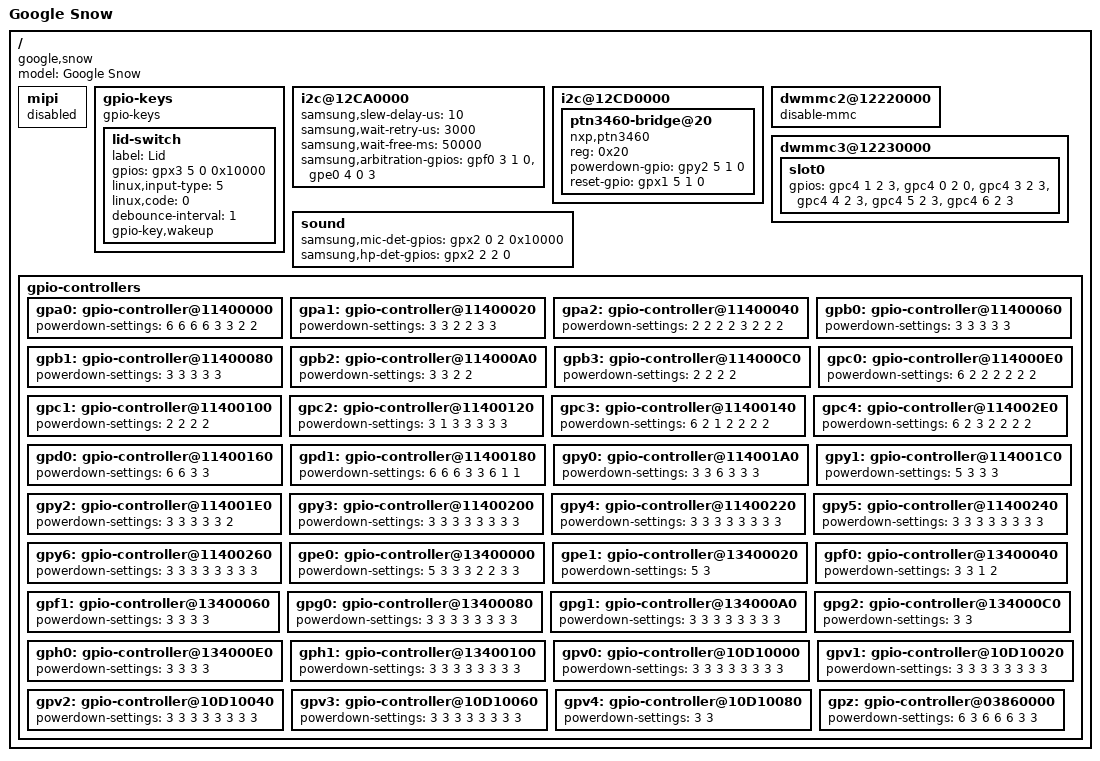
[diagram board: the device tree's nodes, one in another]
/*
 * Google Snow board device tree source
 *
 * Copyright (c) 2012 Google, Inc
 *
 * This program is free software; you can redistribute it and/or modify
 * it under the terms of the GNU General Public License version 2 as
 * published by the Free Software Foundation.
*/

/dts-v1/;
/include/ "exynos5250.dtsi"
/include/ "cros5250-common.dtsi"

/ {
	model = "Google Snow";
	compatible = "google,snow", "samsung,exynos5250";

	mipi {
		status = "disabled";
	};

	gpio-keys {
		compatible = "gpio-keys";

		lid-switch {
			label = "Lid";
			gpios = <&gpx3 5 0 0x10000 0>;
			linux,input-type = <5>; /* EV_SW */
			linux,code = <0>; /* SW_LID */
			debounce-interval = <1>;
			gpio-key,wakeup;
		};
	};
	i2c@12CA0000 {
		samsung,slew-delay-us = <10>;
		samsung,wait-retry-us = <3000>;
		samsung,wait-free-ms = <50000>;
		samsung,arbitration-gpios = <&gpf0 3 1 0 0>,
			<&gpe0 4 0 3 0>;
	};
	i2c@12CD0000 {
		ptn3460-bridge@20 {
			compatible = "nxp,ptn3460";
			reg = <0x20>;
			powerdown-gpio = <&gpy2 5 1 0 0>;
			reset-gpio = <&gpx1 5 1 0 0>;
		};
	};

	dwmmc2@12220000 {
		disable-mmc;
	};

	/*
	 * On Snow we've got SIP WiFi and so can keep drive strengths low to
	 * reduce EMI.
	 */
	dwmmc3@12230000 {
		slot0 {
			gpios = <&gpc4 1 2 3 0>, <&gpc4 0 2 0 0>,
				<&gpc4 3 2 3 0>, <&gpc4 4 2 3 0>,
				<&gpc4 5 2 3 0>, <&gpc4 6 2 3 0>;
		};
	};

	sound {
		samsung,mic-det-gpios = <&gpx2 0 2 0x10000 0>;
		samsung,hp-det-gpios = <&gpx2 2 2 0 0>;
	};

	gpio-controllers {
		gpa0: gpio-controller@11400000 {
			powerdown-settings = <6 6 6 6 3 3 2 2>;
		};

		gpa1: gpio-controller@11400020 {
			powerdown-settings = <3 3 2 2 3 3>;
		};

		gpa2: gpio-controller@11400040 {
			powerdown-settings = <2 2 2 2 3 2 2 2>;
		};

		gpb0: gpio-controller@11400060 {
			powerdown-settings = <3 3 3 3 3>;
		};

		gpb1: gpio-controller@11400080 {
			powerdown-settings = <3 3 3 3 3>;
		};

		gpb2: gpio-controller@114000A0 {
			powerdown-settings = <3 3 2 2>;
		};

		gpb3: gpio-controller@114000C0 {
			powerdown-settings = <2 2 2 2>;
		};

		gpc0: gpio-controller@114000E0 {
			powerdown-settings = <6 2 2 2 2 2 2>;
		};

		gpc1: gpio-controller@11400100 {
			powerdown-settings = <2 2 2 2>;
		};

		gpc2: gpio-controller@11400120 {
			powerdown-settings = <3 1 3 3 3 3 3>;
		};

		gpc3: gpio-controller@11400140 {
			powerdown-settings = <6 2 1 2 2 2 2>;
		};

		gpc4: gpio-controller@114002E0 {
			powerdown-settings = <6 2 3 2 2 2 2>;
		};

		gpd0: gpio-controller@11400160 {
			powerdown-settings = <6 6 3 3>;
		};

		gpd1: gpio-controller@11400180 {
			powerdown-settings = <6 6 6 3 3 6 1 1>;
		};

		gpy0: gpio-controller@114001A0 {
			powerdown-settings = <3 3 6 3 3 3>;
		};

		gpy1: gpio-controller@114001C0 {
			powerdown-settings = <5 3 3 3>;
		};

		gpy2: gpio-controller@114001E0 {
			powerdown-settings = <3 3 3 3 3 2>;
		};

		gpy3: gpio-controller@11400200 {
			powerdown-settings = <3 3 3 3 3 3 3 3>;
		};

		gpy4: gpio-controller@11400220 {
			powerdown-settings = <3 3 3 3 3 3 3 3>;
		};

		gpy5: gpio-controller@11400240 {
			powerdown-settings = <3 3 3 3 3 3 3 3>;
		};

		gpy6: gpio-controller@11400260 {
			powerdown-settings = <3 3 3 3 3 3 3 3>;
		};

		/* gpx0: No powerdown mode, uses active mode on suspend */
		/* gpx1: No powerdown mode, uses active mode on suspend */
		/* gpx2: No powerdown mode, uses active mode on suspend */
		/* gpx3: No powerdown mode, uses active mode on suspend */

		gpe0: gpio-controller@13400000 {
			powerdown-settings = <5 3 3 3 2 2 3 3>;
		};

		gpe1: gpio-controller@13400020 {
			powerdown-settings = <5 3>;
		};

		gpf0: gpio-controller@13400040 {
			powerdown-settings = <3 3 1 2>;
		};

		gpf1: gpio-controller@13400060 {
			powerdown-settings = <3 3 3 3>;
		};

		gpg0: gpio-controller@13400080 {
			powerdown-settings = <3 3 3 3 3 3 3 3>;
		};

		gpg1: gpio-controller@134000A0 {
			powerdown-settings = <3 3 3 3 3 3 3 3>;
		};

		gpg2: gpio-controller@134000C0 {
			powerdown-settings = <3 3>;
		};

		gph0: gpio-controller@134000E0 {
			powerdown-settings = <3 3 3 3>;
		};

		gph1: gpio-controller@13400100 {
			powerdown-settings = <3 3 3 3 3 3 3 3>;
		};

		gpv0: gpio-controller@10D10000 {
			powerdown-settings = <3 3 3 3 3 3 3 3>;
		};

		gpv1: gpio-controller@10D10020 {
			powerdown-settings = <3 3 3 3 3 3 3 3>;
		};

		gpv2: gpio-controller@10D10040 {
			powerdown-settings = <3 3 3 3 3 3 3 3>;
		};

		gpv3: gpio-controller@10D10060 {
			powerdown-settings = <3 3 3 3 3 3 3 3>;
		};

		gpv4: gpio-controller@10D10080 {
			powerdown-settings = <3 3>;
		};

		gpz: gpio-controller@03860000 {
			powerdown-settings = <6 3 6 6 6 3 3>;
		};
	};

};
